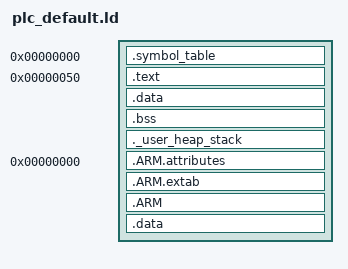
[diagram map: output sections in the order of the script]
/* GROUP(libnosys.a) */

_Min_Heap_Size = 0x00; /* required amount of heap */
_Min_Stack_Size = 0x00; /* required amount of stack */

/* ENTRY(main) */

SECTIONS
{
    . = 0x00000;

    .symbol_table : 
    {
        KEEP(*(*.symbol_table)) 
    }

    . = 0x00050;

    .text : 
    { 
        *(.text) 
        __exidx_start = .;
        __exidx_end = .;
    }

    .data : 
    { 

        *(.data)    

    }

    .bss : 
    { 
        __bss_start__ = .;
        *(.bss)
        __bss_end__ = .;
    }

    /* create this section only for compiler to STFU */
    ._user_heap_stack :
    {
        . = ALIGN(8);
        PROVIDE ( end = . );
        PROVIDE ( _end = . );
        . = . + _Min_Heap_Size;
        . = . + _Min_Stack_Size;
        . = ALIGN(8);
    }

    /* EVERYTHING BELOW THIS LINE IS COPIED FROM STM32F429ZITX_FLASH.ld */


/*
******************************************************************************
**
** @file        : LinkerScript.ld
**
** @author      : Auto-generated by STM32CubeIDE
**
**  Abstract    : Linker script for NUCLEO-F429ZI Board embedding STM32F429ZITx Device from stm32f4 series
**                      2048Kbytes FLASH
**                      64Kbytes CCMRAM
**                      192Kbytes RAM
**
**                Set heap size, stack size and stack location according
**                to application requirements.
**
**                Set memory bank area and size if external memory is used
**
**  Target      : STMicroelectronics STM32
**
**  Distribution: The file is distributed as is, without any warranty
**                of any kind.
**
******************************************************************************
** @attention
**
** Copyright (c) 2024 STMicroelectronics.
** All rights reserved.
**
** This software is licensed under terms that can be found in the LICENSE file
** in the root directory of this software component.
** If no LICENSE file comes with this software, it is provided AS-IS.
**
******************************************************************************
*/


    /* other sections: added only for ompiler to shut up*/
    .ARM.attributes 0 : 
    { 
        *(.ARM.attributes) 
    }

    .ARM.extab   : 
    {
        . = ALIGN(4);
        *(.ARM.extab* .gnu.linkonce.armextab.*)
        . = ALIGN(4);
    }

    .ARM : 
    {
        . = ALIGN(4);
        __exidx_start = .;
        *(.ARM.exidx*)
        __exidx_end = .;
        . = ALIGN(4);
    }

      /* Initialized data sections into "RAM" Ram type memory */
    .data :
    {
        . = ALIGN(4);
        _sdata = .;        /* create a global symbol at data start */
        *(.data)           /* .data sections */
        *(.data*)          /* .data* sections */
        *(.RamFunc)        /* .RamFunc sections */
        *(.RamFunc*)       /* .RamFunc* sections */

        . = ALIGN(4);
        _edata = .;        /* define a global symbol at data end */

    }

    /* Remove information from the compiler libraries */
    /DISCARD/ :
    {
        libc.a ( * )
        libm.a ( * )
        libgcc.a ( * )
    }
}
